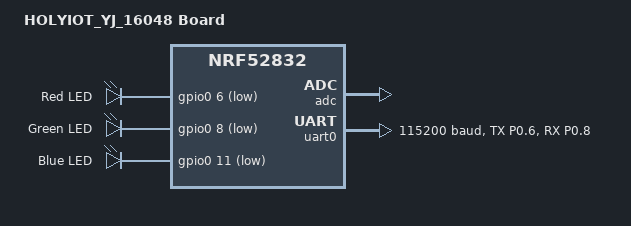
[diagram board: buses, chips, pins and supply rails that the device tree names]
/*
 * Copyright (c) 2020 The ZMK Contributors
 *
 * SPDX-License-Identifier: MIT
 */

/dts-v1/;
#include <nordic/nrf52832_qfaa.dtsi>
#include "mcuboot_partition.dtsi"
#include <dt-bindings/zmk/matrix_transform.h>

/ {
    model = "HOLYIOT_YJ_16048 Board";
	compatible = "holyiot_yj_16048";

	leds {
		compatible = "gpio-leds";
		led0: led_0 {
			gpios = <&gpio0 6 GPIO_ACTIVE_LOW>;
			label = "Red LED";
		};
		led1: led_1 {
			gpios = <&gpio0 8 GPIO_ACTIVE_LOW>;
			label = "Green LED";
		};
		led2: led_2 {
			gpios = <&gpio0 11 GPIO_ACTIVE_LOW>;
			label = "Blue LED";
		};
	};

    aliases {
        led-red = &led0;
        led-green = &led1;
        led-blue = &led2;
    };

};

&gpiote {
	status = "okay";
};

&gpio0 {
	status = "okay";
};

&adc {
	status = "okay";
};

&uart0 {
    current-speed = <115200>;
    status = "okay";
    pinctrl-0 = <&uart0_default>;
    pinctrl-names = "default";
};

&pinctrl {
	uart0_default: uart0_default {
	group1 {
	psels = <NRF_PSEL(UART_TX, 0, 6)>,
	<NRF_PSEL_DISCONNECTED(UART_RTS)>;
	};
	group2 {
	psels = <NRF_PSEL(UART_RX, 0, 8)>,
	<NRF_PSEL_DISCONNECTED(UART_CTS)>;
	bias-pull-up;
	};
	};
	};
